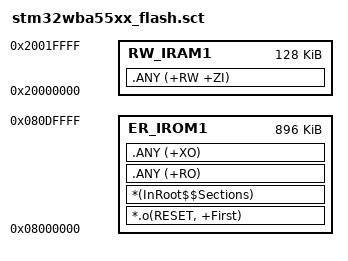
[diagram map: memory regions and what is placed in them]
; *************************************************************
; *** Scatter-Loading Description File                      ***
; *************************************************************
LR_IROM1 0x08000000 0x000E0000 {       ; load region size_region
  ER_IROM1 0x08000000 0x000E0000 { ; load address = execution address
    *.o(RESET, +First)
    *(InRoot$$Sections)
    .ANY (+RO)
    .ANY (+XO)
  }

  RW_IRAM1 0x20000000 0x20000 {
    .ANY (+RW +ZI)
  }
}

;LR_IROM_NVM 0x080FC000 0x4000 {    ; load region size_region
;  ER_IROM_NVM 0x080FC000 0x4000 {  ; load address = execution address
;  }
;}

